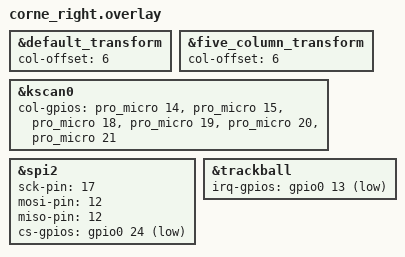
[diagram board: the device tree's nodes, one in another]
/*
 * Copyright (c) 2020 Pete Johanson
 *
 * SPDX-License-Identifier: MIT
 */

#include "corne.dtsi"

&default_transform {
    col-offset = <6>;
};

&five_column_transform {
    col-offset = <6>;
};

&kscan0 {
    col-gpios
        = <&pro_micro 14 GPIO_ACTIVE_HIGH>
        , <&pro_micro 15 GPIO_ACTIVE_HIGH>
        , <&pro_micro 18 GPIO_ACTIVE_HIGH>
        , <&pro_micro 19 GPIO_ACTIVE_HIGH>
        , <&pro_micro 20 GPIO_ACTIVE_HIGH>
        , <&pro_micro 21 GPIO_ACTIVE_HIGH>
        ;
};

/* Enable spi2 bus and the trackball, and define their pins */
&spi2 {
  status = "okay";
  sck-pin = <17>;
  mosi-pin = <12>;
  miso-pin = <12>; // same as mosi (3-wire spi)
  cs-gpios = <&gpio0 24 GPIO_ACTIVE_LOW>;
};

&trackball {
  status = "okay";
  irq-gpios = <&gpio0 13 (GPIO_ACTIVE_LOW | GPIO_PULL_UP)>;
};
